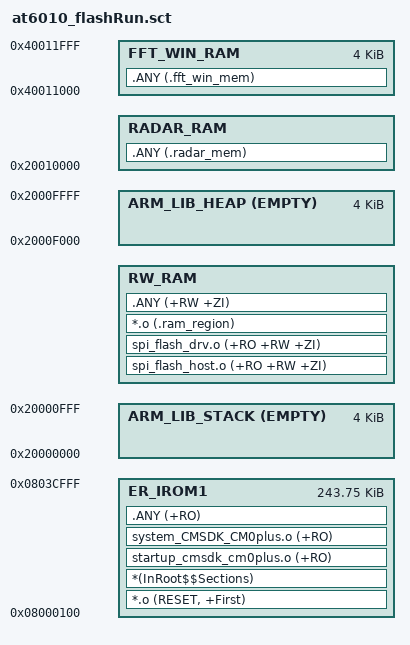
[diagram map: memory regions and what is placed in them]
#! armclang -E --target=arm-arm-none-eabi -mcpu=cortex-m0plus -xc
; *************************************************************
; *** Scatter-Loading Description File generated by uVision ***
; *************************************************************

#define STACK_SIZE        0x1000
#define HEAP_SIZE         0x1000

;总计256KB连续Flash，对应地址：0x0800 0000～0x0803 FFFF,前0x100字节保留不使用,0x0803 D000后开始用于保存系统配置
#define FLASH_BASE        0x08000100
#define FLASE_SIZE        0x0003CF00

;总计192KB连续SRAM，其中前64KB为Retention SRAM,后128KB为非Retention SRAM
#define RAM_BASE          0x20000000
#define RAM_SIZE          0x30000

;雷达DMA仅能访问SRAM后128KB,即：0x2001 0000～0x2002 FFFF
#define RADAR_RAM_BASE      0x20010000

;雷达窗序列专属缓存4KB,即：0x4001 1000～0x4001 1FFF
#define FFT_WIN_BASE        0x40011000


LR_IROM1 FLASH_BASE FLASE_SIZE  {    ; load region size_region
  ER_IROM1 FLASH_BASE FLASE_SIZE  {  ; load address = execution address
   *.o (RESET, +First)
   *(InRoot$$Sections)
   startup_cmsdk_cm0plus.o (+RO)
   system_CMSDK_CM0plus.o (+RO)
   .ANY (+RO)
  }
  
  ; 栈内存分配 (可预留前0x100字节,可以用作向量表)
  ARM_LIB_STACK RAM_BASE +0 ALIGN 8 EMPTY STACK_SIZE {}

  ; 普通内存分配
  RW_RAM +0 {
   ;.ANY (+RO)
   spi_flash_host.o (+RO +RW +ZI)
   spi_flash_drv.o  (+RO +RW +ZI)
   *.o (.ram_region)
   .ANY (+RW +ZI)
  } 
  
  ; 堆内存分配
  ARM_LIB_HEAP RADAR_RAM_BASE ALIGN 8 EMPTY -HEAP_SIZE {}
	  
  ; 雷达DMA专用内存分配(雷达DMA仅能访问SRAM 64KB后,即：0x2001 0000～0x2002 FFFF)
  RADAR_RAM RADAR_RAM_BASE ALIGN 4 {
   .ANY (.radar_mem)
  }
  
  FFT_WIN_RAM  FFT_WIN_BASE 0x1000 {
   .ANY (.fft_win_mem)
  }  
  
  ScatterAssert(ImageLimit(RW_RAM)) <= RADAR_RAM_BASE - HEAP_SIZE ; 检查普通内存终止地址是否超出范围
  ScatterAssert(ImageLimit(RADAR_RAM)) <= RAM_BASE + RAM_SIZE ; 检查雷达专用内存终止地址是否超出芯片SRAM范围
}

